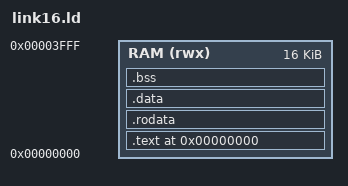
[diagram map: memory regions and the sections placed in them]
OUTPUT_ARCH("riscv")
ENTRY(_start)

MEMORY
{
    RAM (rwx) : ORIGIN = 0x00000000, LENGTH = 16K
}

SECTIONS
{
    . = ORIGIN(RAM);

    .text :
    {
        *(.text.start)
        *(.text*)
    } > RAM

    .rodata :
    {
        *(.rodata*)
    } > RAM

    .data :
    {
        *(.data*)
    } > RAM

    .bss :
    {
        *(.bss*)
        *(COMMON)
    } > RAM

    _end = .;
    _stack_top = ORIGIN(RAM) + LENGTH(RAM);
}
